# DSS_EDP0_COMMON_0_V2A_CORE_VP_REGS_APB register map
Vendor: Texas Instruments
Peripheral module from a debugger description file (folder J7_AHP).
Registers are 32-bit, access not given, reset 0x0 unless marked. A register's access mark holds for its fields unless they carry their own. Offsets are as the file gives them; lines under a group give offsets from that group; [hi:lo] are bit positions; {n}, {i} and the like mark numbered series; 'fields as' and 'values as' point back to an identical list; <NAME> marks a mode.

## DSS_EDP0_COMMON_0_V2A_CORE_VP_REGS_APB (part 1 of 3)
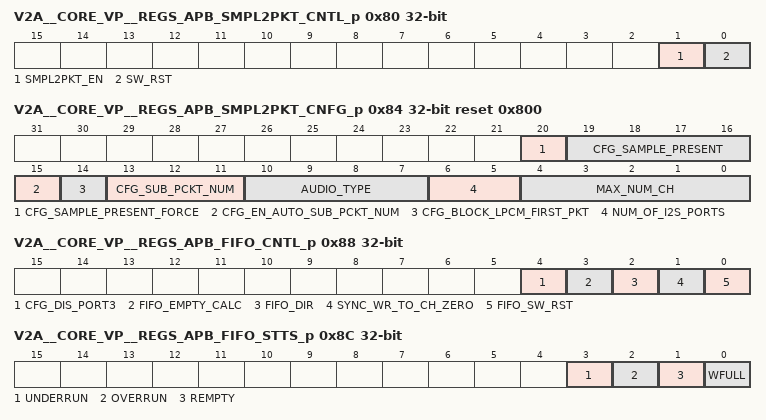
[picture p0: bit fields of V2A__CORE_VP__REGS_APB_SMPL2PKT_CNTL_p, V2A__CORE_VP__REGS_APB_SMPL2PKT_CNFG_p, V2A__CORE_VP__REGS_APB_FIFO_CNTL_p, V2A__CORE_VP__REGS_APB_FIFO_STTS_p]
0x80 V2A__CORE_VP__REGS_APB_SMPL2PKT_CNTL_p
  [1] SMPL2PKT_EN rw — When high Sample to Packets Block starts.
  [0] SW_RST rw — Software reset. Active high.
0x84 V2A__CORE_VP__REGS_APB_SMPL2PKT_CNFG_p reset 0x800
  [20] CFG_SAMPLE_PRESENT_FORCE rw — Force sample present bits
  [19:16] CFG_SAMPLE_PRESENT rw — Sample present bits if force them is active
  [15] CFG_EN_AUTO_SUB_PCKT_NUM rw — Enable automatics sub packet number. When enabled number of sub-packts will be set according to MEM FIFO number of samples.
  [14] CFG_BLOCK_LPCM_FIRST_PKT rw — 0 - All packets behave the same. 1- First lpcm audio packet is sent with 1 - SP.
  [13:11] CFG_SUB_PCKT_NUM rw — Number of sub-packets in HDMI audio 2-ch packet. 00: 1-SP 01: 2-SP 10: 3-SP 11: 4-SP. 100-111: NA.
  [10:7] AUDIO_TYPE rw — Audio Type setting. Packet is structured according to audio type.
  [6:5] NUM_OF_I2S_PORTS rw — Number ofactive I2S ports. 00- 1 port 01-2 ports 11- 4 ports 11 -NA.
  [4:0] MAX_NUM_CH rw — Number of channels to decode. 0: 1 channel 31: 32 channels
0x88 V2A__CORE_VP__REGS_APB_FIFO_CNTL_p
  [4] CFG_DIS_PORT3 rw — 0 - Normal Operation. 1 - I2S port 3 is disabled [user should ignore its outputs]. This allows for 24-ch, 12-ch, 6-ch transfer.
  [3] FIFO_EMPTY_CALC rw — 0 - Empty is a function of read address. 1 - Empty is a function of BASE read address.
  [2] FIFO_DIR rw — 0 - smpl2pkt [inc_step=number of I2S ports] 1 - pkt2smpl [inc_step=num_ch_per_port]
  [1] SYNC_WR_TO_CH_ZERO rw — When high the last channel index synchronizes the write addresses [to the next channel group]
  [0] FIFO_SW_RST rw — Resets Fifo's write and read pointers. When FIFO configuration bits change this signal should be high [due to synchronization issues].
0x8C V2A__CORE_VP__REGS_APB_FIFO_STTS_p
  [3] UNDERRUN ro — Indicates a FIFO underrun error has occured - FIFO read when it was empty. For debug purposes, not synchronized.
  [2] OVERRUN ro — Indicates a FIFO overrun error has occured - FIFO written to when it was full. For debug purposes, not synchronized.
  [1] REMPTY ro — Indicates FIFO Empty. For debug purposes, not synchronized.
  [0] WFULL ro — Indicates FIFO Full. For debug purposes, not synchronized.
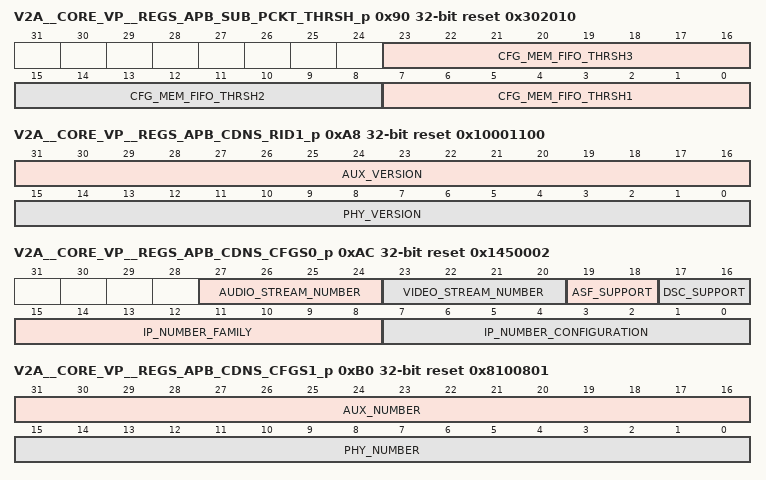
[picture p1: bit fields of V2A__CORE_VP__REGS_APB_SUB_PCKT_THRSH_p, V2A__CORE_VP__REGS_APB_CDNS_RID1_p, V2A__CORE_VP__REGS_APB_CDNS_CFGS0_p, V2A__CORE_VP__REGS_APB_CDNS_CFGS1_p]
0x90 V2A__CORE_VP__REGS_APB_SUB_PCKT_THRSH_p reset 0x302010
  [23:16] CFG_MEM_FIFO_THRSH3 rw — If number of samples in MEM FIFO is below Threshold 3: Each Packet will contain only 3 subpacket.
  [15:8] CFG_MEM_FIFO_THRSH2 rw — If number of samples in MEM FIFO is below Threshold2: Each Packet will contain only 2 subpacket.
  [7:0] CFG_MEM_FIFO_THRSH1 rw — If number of samples in MEM FIFO is below Threshold 1: Each Packet will contain only 1 subpacket.
0xA0 V2A__CORE_VP__REGS_APB_CDNS_DID_p ro reset 0x8546
  [31:0] IPVER — 0x8546 - DisplayPort 1.4/EmbeddedDisplayPort 1.4 Tx Combo Controller
0xA4 V2A__CORE_VP__REGS_APB_CDNS_RID0_p reset 0x2000
  [15:0] IP_VERSION ro — IP version: r[15:4]v[3:0]
0xA8 V2A__CORE_VP__REGS_APB_CDNS_RID1_p ro reset 0x10001100
  [31:16] AUX_VERSION — AUX version: r[31:20]v[19:16]
  [15:0] PHY_VERSION — PHY version: r[15:4]v[3:0]
0xAC V2A__CORE_VP__REGS_APB_CDNS_CFGS0_p reset 0x1450002
  [27:24] AUDIO_STREAM_NUMBER ro — Secondary configuration. Number of audio streams supported
  [23:20] VIDEO_STREAM_NUMBER ro — Secondary configuration. Number of video streams supported
  [19:18] ASF_SUPPORT ro — Secondary configuration. ASF support. 0x0: ASF not supported, 0x1: ASF supported
  [17:16] DSC_SUPPORT ro — Secondary configuration. DSC support. 0x0: DSC not supported, 0x1: DSC supported
  [15:8] IP_NUMBER_FAMILY ro — Main configuration. IP Family Code. 0x00: Display TX Controller, 0x01: Display RX Controller
  [7:0] IP_NUMBER_CONFIGURATION ro — Main configuration. IP configuration. 0x00 - HDMI+DP+HDPC 0x01 - HDMI+HDCP 0x02 - DP+HDCP 0x03 - HDMI+DP
0xB0 V2A__CORE_VP__REGS_APB_CDNS_CFGS1_p ro reset 0x8100801
  [31:16] AUX_NUMBER — AUX IP Number, according to versioning scheme.
  [15:0] PHY_NUMBER — PHY IP Number, according to versioning scheme.
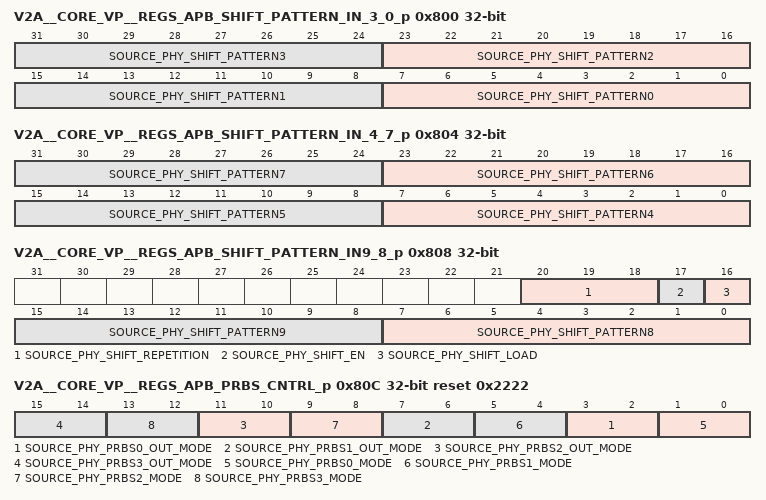
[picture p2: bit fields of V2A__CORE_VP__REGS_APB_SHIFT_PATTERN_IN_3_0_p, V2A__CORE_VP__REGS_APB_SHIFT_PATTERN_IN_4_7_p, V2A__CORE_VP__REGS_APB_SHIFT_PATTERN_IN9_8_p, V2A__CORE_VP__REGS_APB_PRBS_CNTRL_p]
0x800 V2A__CORE_VP__REGS_APB_SHIFT_PATTERN_IN_3_0_p rw
  [8n+7:8n] SOURCE_PHY_SHIFT_PATTERN{n} (n=0..3) — Input to hdmi_pattern_shift
0x804 V2A__CORE_VP__REGS_APB_SHIFT_PATTERN_IN_4_7_p rw
  [8n-25:8n-32] SOURCE_PHY_SHIFT_PATTERN{n} (n=4..7) — Input to hdmi_pattern_shift
0x808 V2A__CORE_VP__REGS_APB_SHIFT_PATTERN_IN9_8_p
  [20:18] SOURCE_PHY_SHIFT_REPETITION rw — Shift repetition Number
  [17] SOURCE_PHY_SHIFT_EN rw — When 1 enable the Shift pattern Mechanism
  [16] SOURCE_PHY_SHIFT_LOAD rw — When 1 load the 80 bits of data
  [15:8] SOURCE_PHY_SHIFT_PATTERN9 rw — Input to hdmi_pattern_shift
  [7:0] SOURCE_PHY_SHIFT_PATTERN8 rw — Input to hdmi_pattern_shift
0x80C V2A__CORE_VP__REGS_APB_PRBS_CNTRL_p reset 0x2222
  [4n+3:4n+2] SOURCE_PHY_PRBS{n}_OUT_MODE rw (n=0..3) — 00 = idle, output all zeros 01 = output 8 bits on pattern[7:0] 10 = output 1 bit on pattern[9] and output inverted bit on pattern[8] 11 = output 10 bits on pattern[9:0]
  [4n+1:4n] SOURCE_PHY_PRBS{n}_MODE rw (n=0..3) — 00 = PRBS11 01 = PRBS15 10 = PRBS7 11 = PRBS31
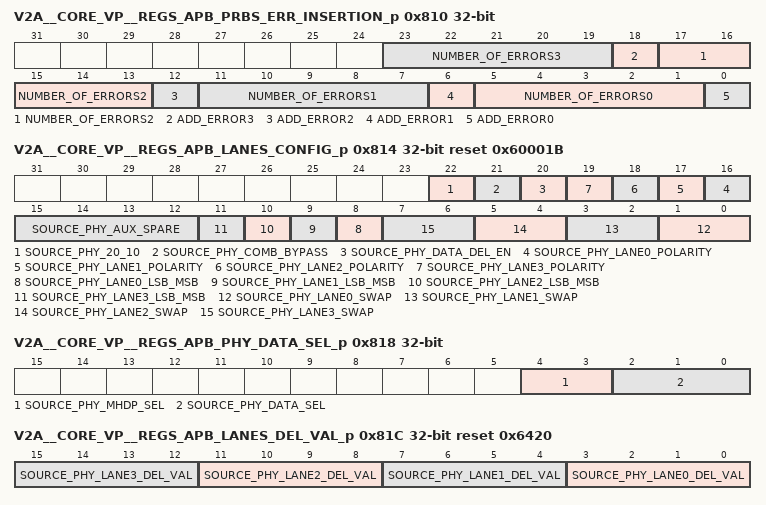
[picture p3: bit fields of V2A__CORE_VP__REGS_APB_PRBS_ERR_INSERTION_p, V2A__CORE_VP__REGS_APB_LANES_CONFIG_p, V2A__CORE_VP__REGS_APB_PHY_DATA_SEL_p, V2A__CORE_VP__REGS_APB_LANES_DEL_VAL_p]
0x810 V2A__CORE_VP__REGS_APB_PRBS_ERR_INSERTION_p
  [6n+5:6n+1] NUMBER_OF_ERRORS{n} rw (n=0..3) — The number of errors to be inserted when add_error is high.
  [18] ADD_ERROR3 rw — When high the PRBS generator inserts the number of errors written in number_of_errors field.
  [12] ADD_ERROR2 rw — When high the PRBS generator inserts the number of errors written in number_of_errors field.
  [6] ADD_ERROR1 rw — When high the PRBS generator inserts the number of errors written in number_of_errors field
  [0] ADD_ERROR0 rw — When high the PRBS generator inserts the number of errors written in number_of_errors field
0x814 V2A__CORE_VP__REGS_APB_LANES_CONFIG_p reset 0x60001B
  [22] SOURCE_PHY_20_10 rw — 1'b0: Data to PHY is 10 bit with char clock 1'd1: Data to PHY is 20 bit with data clock
  [21] SOURCE_PHY_COMB_BYPASS rw — Bypass swap invert and all combination
  [20] SOURCE_PHY_DATA_DEL_EN rw — enable configurable delay of lanes to be activated.if this bit is 0 the delay is only activated for DisplayPort mode with source_phy_data_sel=prbs or shift-mem
  [n+16] SOURCE_PHY_LANE{n}_POLARITY rw (n=0..3) — Reverse polarity of data, lane{n}
  [15:12] SOURCE_PHY_AUX_SPARE rw — Spare bits for aux **1.1**
  [n+8] SOURCE_PHY_LANE{n}_LSB_MSB rw (n=0..3) — Reverse order of data, lane{n}
  [2n+1:2n] SOURCE_PHY_LANE{n}_SWAP rw (n=0..3) — Swap control lane{n}
0x818 V2A__CORE_VP__REGS_APB_PHY_DATA_SEL_p
  [4:3] SOURCE_PHY_MHDP_SEL rw — 3'd0: tx_data = DP 3'd1: tx_data = HDMI 3'd2: tx_data = RSRV 3'd3: tx_data = RSRV
  [2:0] SOURCE_PHY_DATA_SEL rw — 3'd0: tx_data = phy_dout 3'd1: tx_data = phy_dout_bypass 3'd2: tx_data = source_phy_prbs_pout 3'd3: tx_data = source_phy_shift_pout
0x81C V2A__CORE_VP__REGS_APB_LANES_DEL_VAL_p reset 0x6420
  [4n+3:4n] SOURCE_PHY_LANE{n}_DEL_VAL rw (n=0..3) — delay for lane {n} this parameter can take values from 0 up to 8. All other values are reserved
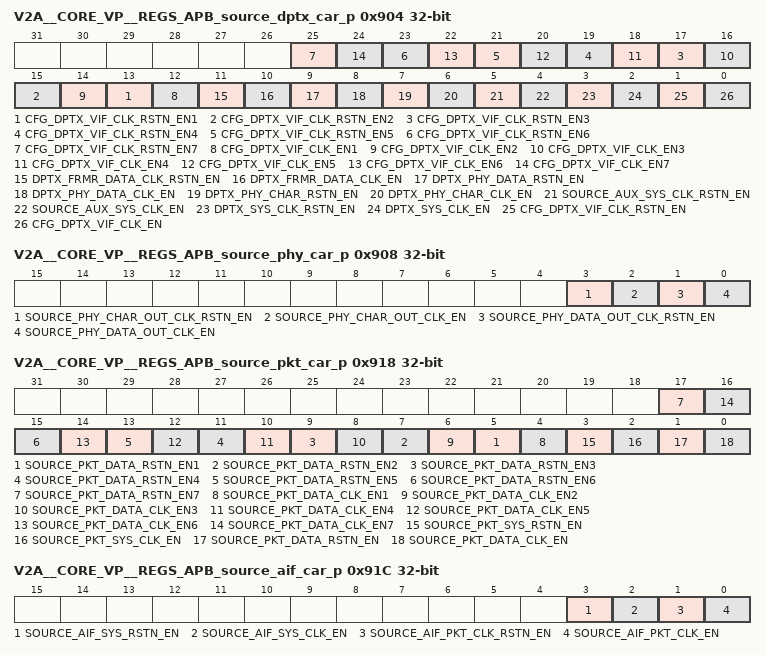
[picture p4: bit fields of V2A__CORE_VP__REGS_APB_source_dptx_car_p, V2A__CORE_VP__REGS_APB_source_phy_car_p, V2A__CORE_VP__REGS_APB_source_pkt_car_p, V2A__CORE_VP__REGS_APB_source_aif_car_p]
0x904 V2A__CORE_VP__REGS_APB_source_dptx_car_p
  [2n+11] CFG_DPTX_VIF_CLK_RSTN_EN{n} rw (n=1..7) — dptx_vif_clk_rstn enable for stream number {n} - active low
  [2n+10] CFG_DPTX_VIF_CLK_EN{n} rw (n=1..7) — dptx_vif_clk enable for stream number {n} - active high
  [11] DPTX_FRMR_DATA_CLK_RSTN_EN rw — dptx_frmr_data_clk_rstn enable - active low
  [10] DPTX_FRMR_DATA_CLK_EN rw — dptx_frmr_data_clk enable - active high
  [9] DPTX_PHY_DATA_RSTN_EN rw — dptx_phy_data_rstn enable - active low
  [8] DPTX_PHY_DATA_CLK_EN rw — dptx_phy_data_clk enable - active high
  [7] DPTX_PHY_CHAR_RSTN_EN rw — dptx_phy_char_rstn enable - active low
  [6] DPTX_PHY_CHAR_CLK_EN rw — dptx_phy_char_clk enable - active high
  [5] SOURCE_AUX_SYS_CLK_RSTN_EN rw — source_aux_sys_clk_rstn enable - active low
  [4] SOURCE_AUX_SYS_CLK_EN rw — source_aux_sys_clk enable - active high
  [3] DPTX_SYS_CLK_RSTN_EN rw — dptx_sys_clk_rstn enable - active low
  [2] DPTX_SYS_CLK_EN rw — dptx_sys_clk enable - active high
  [1] CFG_DPTX_VIF_CLK_RSTN_EN rw — dptx_vif_clk_rstn enable - active low
  [0] CFG_DPTX_VIF_CLK_EN rw — dptx_vif_clk enable - active high
0x908 V2A__CORE_VP__REGS_APB_source_phy_car_p
  [3] SOURCE_PHY_CHAR_OUT_CLK_RSTN_EN rw — source_phy_char_out_clk_rstn enable - active low
  [2] SOURCE_PHY_CHAR_OUT_CLK_EN rw — source_phy_char_out_clk enable - active high
  [1] SOURCE_PHY_DATA_OUT_CLK_RSTN_EN rw — source_phy_data_out_clk_rstn enable - active low
  [0] SOURCE_PHY_DATA_OUT_CLK_EN rw — source_phy_data_out_clk enable - active high
0x918 V2A__CORE_VP__REGS_APB_source_pkt_car_p
  [2n+3] SOURCE_PKT_DATA_RSTN_EN{n} rw (n=1..7) — source_pkt_data_rstn_en{n} - active low
  [2n+2] SOURCE_PKT_DATA_CLK_EN{n} rw (n=1..7) — source_pkt_data_clk_en{n} - active high
  [3] SOURCE_PKT_SYS_RSTN_EN rw — source_pkt_sys_rstn_en - active low
  [2] SOURCE_PKT_SYS_CLK_EN rw — source_pkt_sys_clk_en - active high
  [1] SOURCE_PKT_DATA_RSTN_EN rw — source_pkt_data_rstn_en - active low
  [0] SOURCE_PKT_DATA_CLK_EN rw — source_pkt_data_clk_en - active high
0x91C V2A__CORE_VP__REGS_APB_source_aif_car_p
  [3] SOURCE_AIF_SYS_RSTN_EN rw — source_aif_sys_rstn enable - active low
  [2] SOURCE_AIF_SYS_CLK_EN rw — source_aif_sys_clk enable - active high
  [1] SOURCE_AIF_PKT_CLK_RSTN_EN rw — source_aif_pkt_clk_rstn enable - active low
  [0] SOURCE_AIF_PKT_CLK_EN rw — source_aif_pkt_clk enable - active high
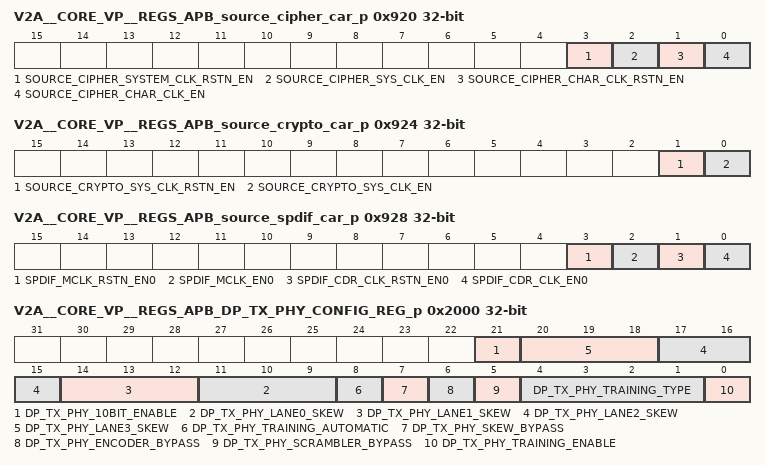
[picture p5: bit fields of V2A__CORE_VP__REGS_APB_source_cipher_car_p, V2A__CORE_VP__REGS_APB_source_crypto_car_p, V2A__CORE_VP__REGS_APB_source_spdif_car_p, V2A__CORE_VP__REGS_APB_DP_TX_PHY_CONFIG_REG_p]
0x920 V2A__CORE_VP__REGS_APB_source_cipher_car_p
  [3] SOURCE_CIPHER_SYSTEM_CLK_RSTN_EN rw — source_cipher_system_clk_rstn enable - active low [Only when HDCP used]
  [2] SOURCE_CIPHER_SYS_CLK_EN rw — source_cipher_sys_clk enable - active high [Only when HDCP used]
  [1] SOURCE_CIPHER_CHAR_CLK_RSTN_EN rw — source_cipher_char_clk_rstn enable - active low [Only when HDCP used]
  [0] SOURCE_CIPHER_CHAR_CLK_EN rw — source_cipher_char_clk enable - active high [Only when HDCP used]
0x924 V2A__CORE_VP__REGS_APB_source_crypto_car_p
  [1] SOURCE_CRYPTO_SYS_CLK_RSTN_EN rw — source_crypto_sys_clk_rstn enable - active low [Only when HDCP used]
  [0] SOURCE_CRYPTO_SYS_CLK_EN rw — source_crypto_sys_clk enable - active high [Only when HDCP used]
0x928 V2A__CORE_VP__REGS_APB_source_spdif_car_p
  [3] SPDIF_MCLK_RSTN_EN0 rw — spdif_mclk_rstn enable0 - active low
  [2] SPDIF_MCLK_EN0 rw — spdif_mclk enable0 - active high
  [1] SPDIF_CDR_CLK_RSTN_EN0 rw — spdif_cdr_clk_rstn enable0 - active low
  [0] SPDIF_CDR_CLK_EN0 rw — spdif_cdr_clk enable0 - active high
0x2000 V2A__CORE_VP__REGS_APB_DP_TX_PHY_CONFIG_REG_p
  [21] DP_TX_PHY_10BIT_ENABLE rw — Used to enable the 10-bit mode. Active high.
  [3n+11:3n+9] DP_TX_PHY_LANE{n}_SKEW rw (n=0..3) — Specifies the programmable lane{n} skew.
  [8] DP_TX_PHY_TRAINING_AUTOMATIC rw — When set, the dp_tx_phy_scrambler_bypass and the dp_tx_phy_encoder_bypass bits are ignored during training pattern generation. This is a debug feature.
  [7] DP_TX_PHY_SKEW_BYPASS rw — Used to bypass the lane skew. Active high. This is a debug feature.
  [6] DP_TX_PHY_ENCODER_BYPASS rw — Used to bypass the encoder. Active high. This is a debug feature.
  [5] DP_TX_PHY_SCRAMBLER_BYPASS rw — Used to bypass the scrambler. Active high. This is a debug feature.
  [4:1] DP_TX_PHY_TRAINING_TYPE rw — Specifies the training pattern type used as follows: 0000 PRBS7 0001 TPS1 0010 TPS2 0011 TPS3 0100 TPS4 0101 custom 80-bit pattern 0110 D10.2 training pattern 0111 Symbol Error Rate Measurement pattern 1000 CP2520 pattern1 1001 CP2520 pattern2 1010 CP2520 pattern3 others reserved
  [0] DP_TX_PHY_TRAINING_ENABLE rw — Enables the training sequence [when set to 1].
0x2004 V2A__CORE_VP__REGS_APB_DP_TX_PHY_SW_RESET_p
  [0] DP_TX_PHY_SW_RST rw — Software reset. Active high.
0x2008 V2A__CORE_VP__REGS_APB_DP_TX_PHY_SCRAMBLER_SEED_p reset 0xFFFF
  [15:0] DP_TX_PHY_SCRAMBLER_SEED rw — Scrambler seed range 0-0xFFFF
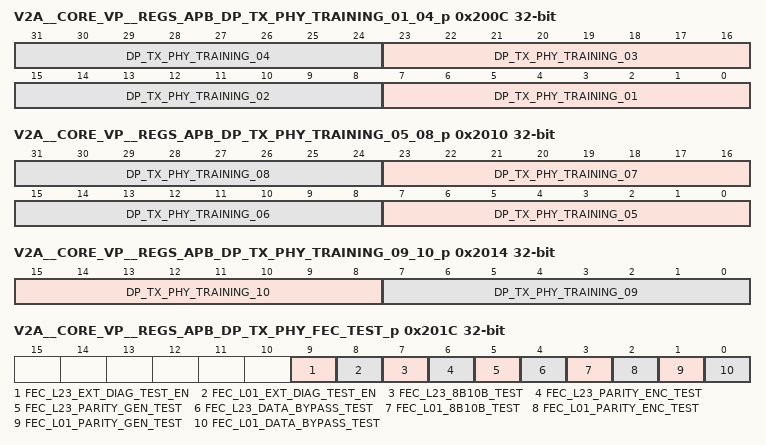
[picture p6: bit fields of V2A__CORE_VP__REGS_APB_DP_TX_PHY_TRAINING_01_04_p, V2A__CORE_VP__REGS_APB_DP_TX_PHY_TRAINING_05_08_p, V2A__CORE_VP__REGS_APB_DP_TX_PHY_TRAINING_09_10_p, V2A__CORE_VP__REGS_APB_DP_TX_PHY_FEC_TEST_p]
0x200C V2A__CORE_VP__REGS_APB_DP_TX_PHY_TRAINING_01_04_p rw
  [8n-1:8n-8] DP_TX_PHY_TRAINING_{n:02} (n=1..4) — Byte {n} of the 80-bit custom training data.
0x2010 V2A__CORE_VP__REGS_APB_DP_TX_PHY_TRAINING_05_08_p rw
  [8n-33:8n-40] DP_TX_PHY_TRAINING_{n:02} (n=5..8) — Byte {n} of the 80-bit custom training data.
0x2014 V2A__CORE_VP__REGS_APB_DP_TX_PHY_TRAINING_09_10_p
  [15:8] DP_TX_PHY_TRAINING_10 rw — Byte 10 of the 80-bit custom training data.
  [7:0] DP_TX_PHY_TRAINING_09 rw — Byte 9 of the 80-bit custom training data.
0x2018 V2A__CORE_VP__REGS_APB_DP_TX_PHY_SR_INTERVAL_p reset 0xFC
  [15:0] DP_TX_PHY_SR_INTERVAL rw — CP2520 test pattern SR Interval definition
0x201C V2A__CORE_VP__REGS_APB_DP_TX_PHY_FEC_TEST_p
  [9] FEC_L23_EXT_DIAG_TEST_EN rw — Encoder 1 external diagnostic test enable. When asserted, a corruption is injected in the external diagnostic reference module which generate an external diagnostic support module fault. To perform external diagnostic test this bit must be set first and then one of the bits 7-4 must be set. Both must be a separate writes. NOTE: This bit cannot be set when bypess, encoder, decoder or 8b10b tests are performed.
  [8] FEC_L01_EXT_DIAG_TEST_EN rw — Encoder 0 external diagnostic test enable. When asserted, a corruption is injected in the external diagnostic reference module which generate an external diagnostic support module fault. To perform external diagnostic test this bit must be set first and then one of the bits 3-0 must be set. Both must be a separate writes. NOTE: This bit cannot be set when bypess, encoder, decoder or 8b10b tests are performed.
  [7] FEC_L23_8B10B_TEST rw — When asserted, a corruption is injected at the interface of the internal diagnostic module which generate a fault in the 8b10b check of the FEC IP datapath for lanes 2 and 3. Bit is self cleared.
  [6] FEC_L23_PARITY_ENC_TEST rw — When asserted, a corruption is injected at the interface of the internal diagnostic module which generate a fault in the parity enc check of the FEC IP datapath for lanes 2 and 3. Bit is self cleared.
  [5] FEC_L23_PARITY_GEN_TEST rw — When asserted, a corruption is injected at the interface of the internal diagnostic module which generate a fault in the parity gen check of the FEC IP datapaths for lanes 2 and 3. Bit is self cleared.
  [4] FEC_L23_DATA_BYPASS_TEST rw — When asserted, a corruption is injected at the interface of the internal diagnostic module which generate a fault in the bypass check for of the FEC IP datapathe for lanes 2 and 3. Bit is self cleared.
  [3] FEC_L01_8B10B_TEST rw — When asserted, a corruption is injected at the interface of the internal diagnostic module which generate a fault in the 8b10b check of the FEC IP datapath for lanes 0 and 1. Bit is self cleared.
  [2] FEC_L01_PARITY_ENC_TEST rw — When asserted, a corruption is injected at the interface of the internal diagnostic module which generate a fault in the parity enc check of the FEC IP datapath for lanes 0 and 1. Bit is self cleared.
  [1] FEC_L01_PARITY_GEN_TEST rw — When asserted, a corruption is injected at the interface of the internal diagnostic module which generate a fault in the parity gen check of the FEC IP datapath for lanes 0 and 1. Bit is self cleared.
  [0] FEC_L01_DATA_BYPASS_TEST rw — When asserted, a corruption is injected at the interface of the internal diagnostic module which generate a fault in the bypass check for of the FEC IP datapath for lanes 0 and 1. Bit is self cleared.
0x2100 V2A__CORE_VP__REGS_APB_HPD_IRQ_DET_MIN_TIMER_p reset 0xC350
  [23:0] HPD_IRQ_DET_MIN_TIMER rw — HPD min timer for interrupt.
0x2104 V2A__CORE_VP__REGS_APB_HPD_IRQ_DET_MAX_TIMER_p reset 0x186A0
  [23:0] HPD_IRQ_DET_MAX_TIMER rw — HPD max timer
0x2108 V2A__CORE_VP__REGS_APB_HPD_UNPLGED_DET_MIN_TIMER_p reset 0x30D40
  [23:0] HPD_UNPLGED_DET_MIN_TIMER rw — HPD unplugged timer
0x210C V2A__CORE_VP__REGS_APB_HPD_STABLE_TIMER_p reset 0x186A0
  [23:0] HPD_STABLE_TIMER rw — HPD stable timer counter setup.
0x2110 V2A__CORE_VP__REGS_APB_HPD_FILTER_TIMER_p reset 0x7A12
  [23:0] HPD_FILTER_TIMER rw — HPD glitch filter counter setup.
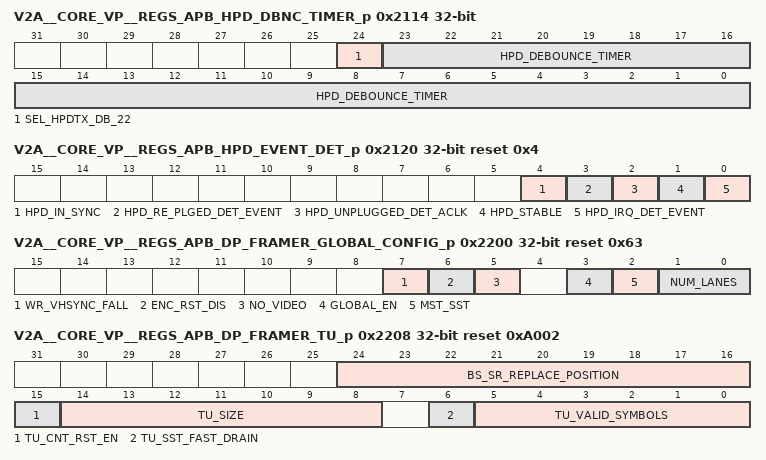
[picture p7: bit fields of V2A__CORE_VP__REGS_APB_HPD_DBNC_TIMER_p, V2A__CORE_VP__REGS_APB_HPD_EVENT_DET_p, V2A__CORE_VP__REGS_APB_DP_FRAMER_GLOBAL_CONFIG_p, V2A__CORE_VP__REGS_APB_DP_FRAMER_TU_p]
0x2114 V2A__CORE_VP__REGS_APB_HPD_DBNC_TIMER_p
  [24] SEL_HPDTX_DB_22 rw — Debouncer enable 0 - debouncer disabled 1 - debouncer enabled
  [23:0] HPD_DEBOUNCE_TIMER rw — HPD debounce timer setup.
0x211C V2A__CORE_VP__REGS_APB_HPD_EVENT_MASK_p
  [3:0] HPD_EVENTS_MASK rw — HPD mask events
0x2120 V2A__CORE_VP__REGS_APB_HPD_EVENT_DET_p reset 0x4
  [4] HPD_IN_SYNC ro — HDP in sync detected
  [3] HPD_RE_PLGED_DET_EVENT ro — HPD Re-Plugged event detected.
  [2] HPD_UNPLUGGED_DET_ACLK ro — HPD Un-Plugged event detected.
  [1] HPD_STABLE ro — HPD Stable indication
  [0] HPD_IRQ_DET_EVENT ro — Bit 0 - HPD irq event
0x2200 V2A__CORE_VP__REGS_APB_DP_FRAMER_GLOBAL_CONFIG_p reset 0x63
  [7] WR_VHSYNC_FALL rw — When set to 1 change the write state machine to sync on falling edge of vsync. Used only for debug purpose.
  [6] ENC_RST_DIS rw — Unused. Kept RW for software backward compatibility.
  [5] NO_VIDEO rw — No-video mode configuration bit. Relevant only in SST mode. When this bit is set high and framer is enabled then IP operates in no-video mode i.e. BS symbol is generated every 8192 link symbols. In this mode audio data can be transmitted.
  [3] GLOBAL_EN rw — Global enable for complete Framer module, active high. It is deasserted during configuration phase. Once configuration is finished, it is asserted.
  [2] MST_SST rw — Mode select: 0 - SST mode 1 - MST mode Static cofiguration bit that must be set before link training.
  [1:0] NUM_LANES rw — Number of lanes: 0h - One lane [Lane 0 only] 1h - Two lanes [Lanes 0 and 1 only] 2h - Reserved 3h - Four lanes [Lanes 0, 1, 2, and 3]. This value can only be changed before link training and further it can by modified during link training in case link training for a given lane configuration fails. This field must not be changed after link training.
0x2204 V2A__CORE_VP__REGS_APB_DP_SW_RESET_p
  [0] SW_RST rw — Unused. Kept RW for software backward compatibility.
0x2208 V2A__CORE_VP__REGS_APB_DP_FRAMER_TU_p reset 0xA002
  [24:16] BS_SR_REPLACE_POSITION rw — Static debug register. When set to non-zero value, the BS counter will be reinitialized to this value that will result in earlier initial SR insertion.
  [15] TU_CNT_RST_EN rw — Unused. Kept RW for software backward compatibility.
  [14:8] TU_SIZE rw — Transfer Unit size. Even values between 32 and 64 are supported.
  [6] TU_SST_FAST_DRAIN rw — Allow the video FIFO to drain faster at end of line. This setting applies only to SST mode.
  [5:0] TU_VALID_SYMBOLS rw — Number of valid symbols per Transfer Unit [TU]. Rounded down to lower integer value [refer to equation in DP specification]. Allowed values are 1 to [TU_size-1]. TU valid smaller than one that would result this register to be set to 0 are not supported by the IP. This setting applies only to SST mode.
0x2218 V2A__CORE_VP__REGS_APB_DP_FRAMER_BS_SR_INTRVL_p reset 0x200
  [9:0] BS_SR_INTERVAL rw — Static debug register. Controls how often BS is replaced by SR in SST mode. Default value of 512 results in every 512th BS being replaced by SR as per DP spec. This register can only be changed for a test purposes in order to speed up BS-SR replacement.
0x2258 V2A__CORE_VP__REGS_APB_DP_MTPH_ECF_SLOTS_31_0_p rw
  [31:0] TSLOT_ENCRYPT31_0
0x225C V2A__CORE_VP__REGS_APB_DP_MTPH_ECF_SLOTS_63_32_p rw
  [31:0] TSLOT_ENCRYPT63_32
0x2260 V2A__CORE_VP__REGS_APB_DP_MTPH_LVP_SYMBOL_p reset 0x531F
  [15:0] MTPH_LVP_SYM rw — Symbol value for LINK VERIFICATION PATTERN [LVP]
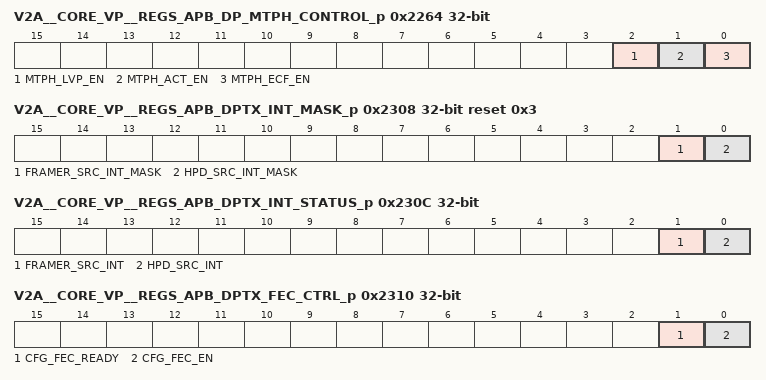
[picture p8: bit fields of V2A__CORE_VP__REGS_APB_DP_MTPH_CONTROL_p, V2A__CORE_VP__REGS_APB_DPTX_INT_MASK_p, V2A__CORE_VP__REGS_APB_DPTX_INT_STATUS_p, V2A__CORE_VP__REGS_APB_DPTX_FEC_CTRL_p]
0x2264 V2A__CORE_VP__REGS_APB_DP_MTPH_CONTROL_p
  [2] MTPH_LVP_EN rw — Unused. Kept RW for software backward compatibility.
  [1] MTPH_ACT_EN wo — MST feature when written with value 1, an ACT sequence will be triggered for slot allocation control. This bit is write only.
  [0] MTPH_ECF_EN rw — Unused. Kept RW for software backward compatibility.
0x226C V2A__CORE_VP__REGS_APB_DP_MTPH_STATUS_p
  [0] MTPH_ACT_STATUS ro — Status of ACT insertion. Returns 1 until ACT sequence completes.
0x2300 V2A__CORE_VP__REGS_APB_DPTX_LANE_EN_p
  [3:0] DPTX_LANE_ENABLE rw — DPTX lane enable each lane as a bit when 1 lane is enabled
0x2304 V2A__CORE_VP__REGS_APB_DPTX_ENHNCD_p
  [0] DPTX_ENHANCED_MODE rw — Enhanced mode control 0x0 - enhanced mode disabled 0x1 - enhanced mode enabled. Enhanced mode should always be enabled if Sink supports it.
0x2308 V2A__CORE_VP__REGS_APB_DPTX_INT_MASK_p reset 0x3
  [1] FRAMER_SRC_INT_MASK rw — Framer mask interrupt 0x0-interrupt enabled 0x1-interrupt disabled
  [0] HPD_SRC_INT_MASK rw — HPD mask interrupt 0x0-interrupt enabled 0x1-interrupt disabled
0x230C V2A__CORE_VP__REGS_APB_DPTX_INT_STATUS_p
  [1] FRAMER_SRC_INT ro — Framer interrupt - not used.
  [0] HPD_SRC_INT ro — HPD interrupt. Active HIGH. If set further status can be read from HPD_EVENT_DET register. This bit is automatically cleared on read from HPD_EVENT_DET register.
0x2310 V2A__CORE_VP__REGS_APB_DPTX_FEC_CTRL_p
  [1] CFG_FEC_READY rw — Equivalent DPCD register FEC_READY, enable alternative CP coding. This bit must be set high before link training if FEC is going to be enabled.
  [0] CFG_FEC_EN rw — FEC Enable 1-enabled 0-disabled. This bit can be changed on when there is no video transmission [and cfg_fec_ready was set before link training].
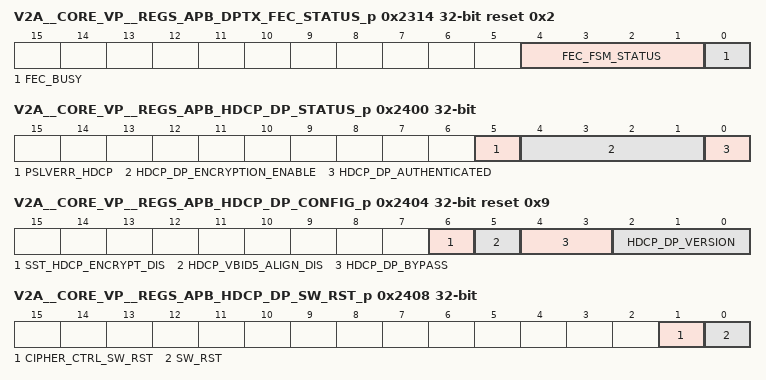
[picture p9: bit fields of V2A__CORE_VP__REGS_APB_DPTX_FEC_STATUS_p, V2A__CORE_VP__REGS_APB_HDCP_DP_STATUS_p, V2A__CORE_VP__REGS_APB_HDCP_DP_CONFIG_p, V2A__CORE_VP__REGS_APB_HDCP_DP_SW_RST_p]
0x2314 V2A__CORE_VP__REGS_APB_DPTX_FEC_STATUS_p reset 0x2
  [4:1] FEC_FSM_STATUS ro — FEC FSM status, 1-FEC is off, 2-generate enable sequence, 4-normal work, 8-generate disable sequence. Used for debug purposes only.
  [0] FEC_BUSY ro — FEC Active status. Set in line with first symbol of FEC_DECODE_EN sequence and de-asserts in line with last symbol of FEC_DECODE_DIS sequence.
0x2400 V2A__CORE_VP__REGS_APB_HDCP_DP_STATUS_p
  [5] PSLVERR_HDCP ro — APB slave error status from HDCP module has been reported when this bit is set to 1.
  [4:1] HDCP_DP_ENCRYPTION_ENABLE ro — Encryption is enabled when this bit is set to 1.
  [0] HDCP_DP_AUTHENTICATED ro — HDCP 1.3 authentication is enabled when this bit is set to 1.
0x2404 V2A__CORE_VP__REGS_APB_HDCP_DP_CONFIG_p reset 0x9
  [6] SST_HDCP_ENCRYPT_DIS rw — Disable automatic HDCP encryption in SST mode when cipher is authenticated. This bit can also be set to 1 to disable encryption
  [5] HDCP_VBID5_ALIGN_DIS rw — Debug register, no longer used.
  [4:3] HDCP_DP_BYPASS rw — HDCP DP bypass. No-bypass must be set prior link training if HDCP is going to be used. This field must not be changed during operation. 0x0-No bypass; 0x1-Bypass enabled; All other combinations reserved.
  [2:0] HDCP_DP_VERSION rw — HDCP version. 0x1-HDCP2.2; 0x2-HDCP1.4; Other-Reserved
0x2408 V2A__CORE_VP__REGS_APB_HDCP_DP_SW_RST_p
  [1] CIPHER_CTRL_SW_RST rw — Software reset of cipher control logic only.
  [0] SW_RST rw — Software reset.
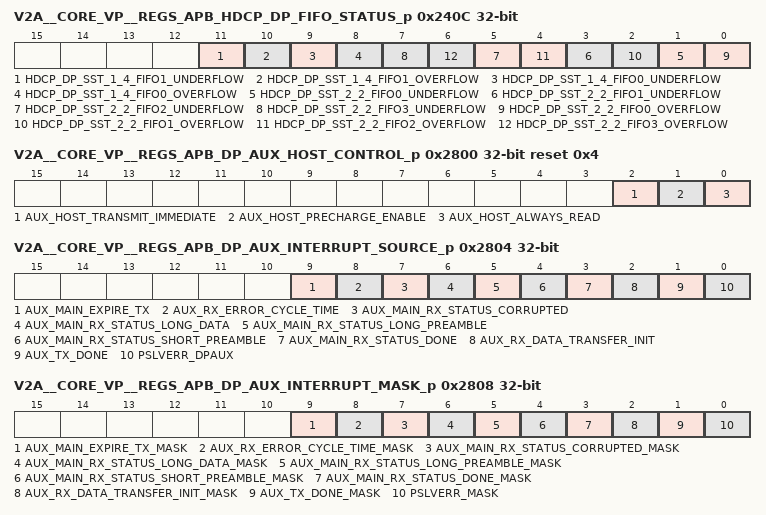
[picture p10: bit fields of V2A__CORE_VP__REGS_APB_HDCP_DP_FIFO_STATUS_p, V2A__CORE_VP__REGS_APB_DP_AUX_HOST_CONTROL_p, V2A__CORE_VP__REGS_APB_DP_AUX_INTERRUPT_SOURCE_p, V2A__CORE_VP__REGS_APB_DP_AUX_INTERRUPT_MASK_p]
0x240C V2A__CORE_VP__REGS_APB_HDCP_DP_FIFO_STATUS_p
  [11] HDCP_DP_SST_1_4_FIFO1_UNDERFLOW ro — SST HDCP1.4 fifo1 underflow.
  [10] HDCP_DP_SST_1_4_FIFO1_OVERFLOW ro — SST HDCP1.4 fifo1 overflow.
  [9] HDCP_DP_SST_1_4_FIFO0_UNDERFLOW ro — SST HDCP1.4 fifo0 underflow.
  [8] HDCP_DP_SST_1_4_FIFO0_OVERFLOW ro — SST HDCP1.4 fifo0 overflow.
  [2n+1] HDCP_DP_SST_2_2_FIFO{n}_UNDERFLOW ro (n=0..3) — SST HDCP2.2 fifo{n} underflow.
  [2n] HDCP_DP_SST_2_2_FIFO{n}_OVERFLOW ro (n=0..3) — SST HDCP2.2 fifo{n} overflow.
0x2800 V2A__CORE_VP__REGS_APB_DP_AUX_HOST_CONTROL_p reset 0x4
  [2] AUX_HOST_TRANSMIT_IMMEDIATE rw — This bit is used only in DP_OUT mode. If SET, a transaction that comes from the adapter will be sent immediately without waiting for send_external_transaction pulse. If CLEAR, the MC controls the traffic to/from the adapter.
  [1] AUX_HOST_PRECHARGE_ENABLE rw — According to the current standard the tx precharge is done by sending 10 to 16 data_0 on the line before the SYNC. Old standard define the precharge by forcing the AFE to be in precharge mode before transmitting the SYNC.
  [0] AUX_HOST_ALWAYS_READ rw — Normally, the aux_rx is disabled during transmit. Setting this bit allow loopback operation and all transmit transactions will go to the receiver. Used for debug purpose.
0x2804 V2A__CORE_VP__REGS_APB_DP_AUX_INTERRUPT_SOURCE_p
  [9] AUX_MAIN_EXPIRE_TX ro — Timer expire [external] in DP_OUT. Active HIGH. Clear on read.
  [8] AUX_RX_ERROR_CYCLE_TIME ro — Cycle time error. Asserted if aux_rx_last_cycle is less then aux_host_1m_min or greater then aux_host_1m_max. Active HIGH. Clear on read.
  [7] AUX_MAIN_RX_STATUS_CORRUPTED ro — The received transaction corrupted during the data phase [bad STOP, or unaligned STOP]. Active HIGH. Clear on read.
  [6] AUX_MAIN_RX_STATUS_LONG_DATA ro — The received transaction had more than 20 data bytes. Active HIGH. Clear on read.
  [5] AUX_MAIN_RX_STATUS_LONG_PREAMBLE ro — The received transaction had preamble greater than the preamble_max. Active HIGH. Clear on read.
  [4] AUX_MAIN_RX_STATUS_SHORT_PREAMBLE ro — The received transaction had preamble shorter than the preamble_max. Active HIGH. Clear on read.
  [3] AUX_MAIN_RX_STATUS_DONE ro — This module control the packet extraction and packet read from the memory. Active HIGH. Clear on read.
  [2] AUX_RX_DATA_TRANSFER_INIT ro — Rx data transfer may be initiated. Falling edge of the aux_mailbox_empty. Active HIGH. Clear on read.
  [1] AUX_TX_DONE ro — Tx data transfer finished. Active HIGH. Clear on read.
  [0] PSLVERR_DPAUX ro — APB slave error interrupt from DP AUX module. Active HIGH. Clear on read.
0x2808 V2A__CORE_VP__REGS_APB_DP_AUX_INTERRUPT_MASK_p
  [9] AUX_MAIN_EXPIRE_TX_MASK rw — aux_main_expire_external mask 0x0-interrupt enabled 0x1-interrupt disabled
  [8] AUX_RX_ERROR_CYCLE_TIME_MASK rw — aux_rx_error_cycle_time mask 0x0-interrupt enabled 0x1-interrupt disabled
  [7] AUX_MAIN_RX_STATUS_CORRUPTED_MASK rw — aux_main_rx_status_corrupted_mask 0x0-interrupt enabled 0x1-interrupt disabled
  [6] AUX_MAIN_RX_STATUS_LONG_DATA_MASK rw — aux_main_rx_status_long_data_mask 0x0-interrupt enabled 0x1-interrupt disabled
  [5] AUX_MAIN_RX_STATUS_LONG_PREAMBLE_MASK rw — aux_main_rx_status_long_preamble_mask 0x0-interrupt enabled 0x1-interrupt disabled
  [4] AUX_MAIN_RX_STATUS_SHORT_PREAMBLE_MASK rw — aux_main_rx_status_short_preamble_mask 0x0-interrupt enabled 0x1-interrupt disabled
  [3] AUX_MAIN_RX_STATUS_DONE_MASK rw — aux_main_rx_status_done_mask 0x0-interrupt enabled 0x1-interrupt disabled
  [2] AUX_RX_DATA_TRANSFER_INIT_MASK rw — rx_data_transfer_init mask 0x0-interrupt enabled 0x1-interrupt disabled
  [1] AUX_TX_DONE_MASK rw — aux_tx_done_mask 0x0-interrupt enabled 0x1-interrupt disabled
  [0] PSLVERR_MASK rw — Mask for pslverr_dpaux interrupt. 0x0-interrupt enabled 0x1-interrupt disabled
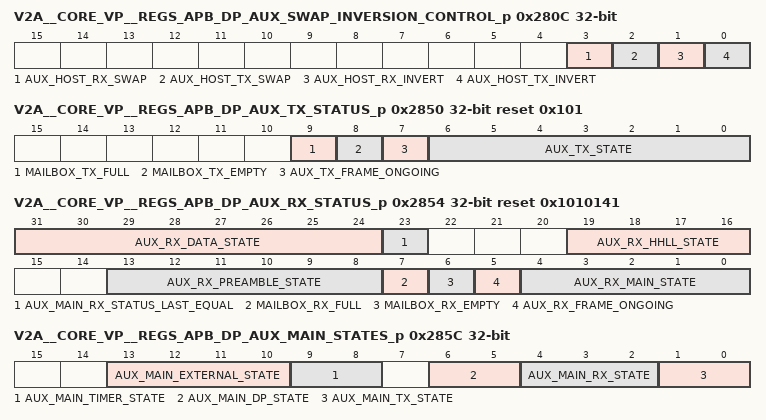
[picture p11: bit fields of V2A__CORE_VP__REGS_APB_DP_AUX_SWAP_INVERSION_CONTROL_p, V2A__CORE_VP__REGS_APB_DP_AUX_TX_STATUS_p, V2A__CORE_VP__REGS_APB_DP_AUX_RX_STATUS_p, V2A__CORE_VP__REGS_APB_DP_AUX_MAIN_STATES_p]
0x280C V2A__CORE_VP__REGS_APB_DP_AUX_SWAP_INVERSION_CONTROL_p
  [3] AUX_HOST_RX_SWAP rw — Shift right [LSB first] of the income data
  [2] AUX_HOST_TX_SWAP rw — Shift right the output data [LSB first]
  [1] AUX_HOST_RX_INVERT rw — Invert rx input and output data to AUXILIARY CHANNEL
  [0] AUX_HOST_TX_INVERT rw — Invert tx input and output data to AUXILIARY CHANNEL
0x2810 V2A__CORE_VP__REGS_APB_DP_AUX_SEND_NACK_TRANSACTION_p
  [0] AUX_HOST_SEND_NACK_TRANSACTION rw — Send nack transaction by AUX_TX. This bit is automatically cleared when operation in completed.
0x2814 V2A__CORE_VP__REGS_APB_DP_AUX_CLEAR_RX_p
  [0] AUX_HOST_CLEAR_RX rw — Clear all rx bits in register 64,65.This command is an indication that the processing of last receive transaction was completed and the AUX_RX can start looking for new receive transaction. This bit is automatically cleared when operation in completed.
0x2818 V2A__CORE_VP__REGS_APB_DP_AUX_CLEAR_TX_p
  [0] AUX_HOST_CLEAR_TX rw — Clear all external bits in registers 64,67.This command used in DP_IN mode. It is an indication that the processing of last external transaction was completed and the DP_AUX can start receive new external transaction from the adapter. This bit is automatically cleared when operation in completed.
0x281C V2A__CORE_VP__REGS_APB_DP_AUX_TIMER_STOP_p
  [0] AUX_HOST_STOP_TIMER rw — Stop timer operation.
0x2820 V2A__CORE_VP__REGS_APB_DP_AUX_TIMER_CLEAR_p
  [0] AUX_HOST_CLEAR_TIMER rw — Stop timer operation. This bit is automatically cleared when operation in completed.
0x2824 V2A__CORE_VP__REGS_APB_DP_AUX_RESET_SW_p
  [0] AUX_HOST_SW_RESET rw — Reset all DP_AUX state machines and clear all the status bits. The registers value remains. [S/W reset]. This bit is automatically cleared when operation in completed.
0x2828 V2A__CORE_VP__REGS_APB_DP_AUX_DIVIDE_2M_p reset 0xB
  [7:0] AUX_HOST_DIVIDE_2M rw — The ratio between sys_clk and 2MHz, [[sys_clk frequency/2MHz] - 1], for 25MHz sys_clk the value is 11. This register is used by AUX_TX for generating the AUX_TX clock.
0x282C V2A__CORE_VP__REGS_APB_DP_AUX_TX_PREACHARGE_LENGTH_p reset 0x10
  [5:0] AUX_HOST_PRECHARGE_LENGTH rw — Length of pre charge field, standard definition is 10 to 16 bits/clocks.
0x2830 V2A__CORE_VP__REGS_APB_DP_AUX_FREQUENCY_1M_MAX_p reset 0x22
  [10:0] AUX_HOST_1M_MAX rw — The maximum legal frequency receiving from the line by the standard is 1.25MHz.The calculation is:[1.25 MHz cycle time]/[sys_clk[-15%] cycle time] 800/46 =17
0x2834 V2A__CORE_VP__REGS_APB_DP_AUX_FREQUENCY_1M_MIN_p reset 0x9
  [10:0] AUX_HOST_1M_MIN rw — The minimum legal frequency receiving from the line by the standard is 0.83MHz.The calculation is:[0.83 MHz cycle time]/[sys_clk[+15%] cycle time] 1200/34 =35
0x2838 V2A__CORE_VP__REGS_APB_DP_AUX_RX_PRE_MIN_p reset 0x1A
  [5:0] AUX_HOST_PRE_MIN rw — Valid minimum length of preamble during receive. The standard defines pre_min=26 The value of this register should be greater then the average_number_of_cycles defined in reg 0 [2 , 4 or 8 ]
0x283C V2A__CORE_VP__REGS_APB_DP_AUX_RX_PRE_MAX_p reset 0x20
  [5:0] AUX_HOST_PRE_MAX rw — Valid maximum length of preamble during receive. The standard defines pre_max = 32
0x2840 V2A__CORE_VP__REGS_APB_DP_AUX_TIMER_PRESET_p reset 0x1D4C
  [15:0] AUX_HOST_TIMER_PRESET rw — The preset value of the timer in DP_IN mode. With sys_clk= 25MHz the Timer can measure up to ~2500 micro seconds. The defaults value is 300us [0x1D4c]
0x2844 V2A__CORE_VP__REGS_APB_DP_AUX_NACK_FORMAT_p reset 0x20
  [7:0] AUX_HOST_NACK_FORMAT rw — Nack or defer pattern for transmit [ 00100000 for defer, 00010000 for nack]
0x2848 V2A__CORE_VP__REGS_APB_DP_AUX_TX_DATA_p
  [9:0] MAILBOX_TX_DATA rw — TX data byte written to the mailbox. It is written 20 times and directly transferred into TX mailbox. First 8 bits are regular data. When the first data is transferred into mailbox mailbox_tx_data[8] [frame start] is set to 1. When the last data is transferred into mailbox, mailbox_tx_data[9] [frame_end] is set to 1.
0x284C V2A__CORE_VP__REGS_APB_DP_AUX_RX_DATA_p
  [9:0] MAILBOX_RX_DATA ro — Read data from the mailbox. Whenever read to this register occurs, aux_mailbox_read to RX Mailbox shall be asserted for one clock cycle.
0x2850 V2A__CORE_VP__REGS_APB_DP_AUX_TX_STATUS_p reset 0x101
  [9] MAILBOX_TX_FULL ro — AUX Mailbox TX full flag.
  [8] MAILBOX_TX_EMPTY ro — AUX Mailbox TX empty flag.
  [7] AUX_TX_FRAME_ONGOING ro — Frame transmission status.
  [6:0] AUX_TX_STATE ro — Aux_tx state machine register.
0x2854 V2A__CORE_VP__REGS_APB_DP_AUX_RX_STATUS_p reset 0x1010141
  [31:24] AUX_RX_DATA_STATE ro — AUX_RX SM state.
  [23] AUX_MAIN_RX_STATUS_LAST_EQUAL ro — The receive transaction is equal to the previous transaction.
  [19:16] AUX_RX_HHLL_STATE ro — AUX_RX hhll state machine register.
  [13:8] AUX_RX_PREAMBLE_STATE ro — AUX_RX preamble state machine register. Used only for debug.
  [7] MAILBOX_RX_FULL ro — AUX Mailbox RX full flag.
  [6] MAILBOX_RX_EMPTY ro — AUX Mailbox RX empty flag.
  [5] AUX_RX_FRAME_ONGOING ro — Frame reception status.
  [4:0] AUX_RX_MAIN_STATE ro — AUX_RX main state machine register. Used only for debug purpose.
0x2858 V2A__CORE_VP__REGS_APB_DP_AUX_RX_CYCLE_COUNTER_p
  [10:0] AUX_RX_CYCLE_COUNTER ro — Count system clocks from last change in the auxiliary line input.
0x285C V2A__CORE_VP__REGS_APB_DP_AUX_MAIN_STATES_p
  [13:10] AUX_MAIN_EXTERNAL_STATE ro — AUX_MAIN external state machine register.
  [9:8] AUX_MAIN_TIMER_STATE ro — AUX_MAIN timer state machine.
  [6:5] AUX_MAIN_DP_STATE ro — AUX_MAIN dp state machine.
  [4:2] AUX_MAIN_RX_STATE ro — AUX_MAIN rx state machine.
  [1:0] AUX_MAIN_TX_STATE ro — AUX_MAIN tx state machine.
0x2860 V2A__CORE_VP__REGS_APB_DP_AUX_MAIN_TIMER_p
  [15:0] AUX_MAIN_TIMER ro — DP_AUX MAIN timer status.
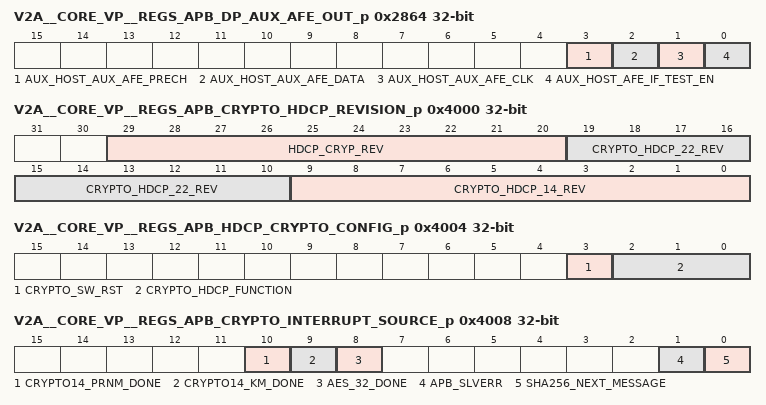
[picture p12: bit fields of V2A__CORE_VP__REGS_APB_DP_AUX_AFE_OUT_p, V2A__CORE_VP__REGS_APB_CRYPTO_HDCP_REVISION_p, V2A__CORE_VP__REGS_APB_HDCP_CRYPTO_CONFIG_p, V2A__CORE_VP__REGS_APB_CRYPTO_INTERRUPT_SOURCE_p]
0x2864 V2A__CORE_VP__REGS_APB_DP_AUX_AFE_OUT_p
  [3] AUX_HOST_AUX_AFE_PRECH rw — Drive the aux_data_prech output to the AFE when aux_host_afe_if_test_en [bit 0 ] is set.
  [2] AUX_HOST_AUX_AFE_DATA rw — Drive the aux_data_out output to the AFE when aux_host_afe_if_test_en [bit 0 ] is set.
  [1] AUX_HOST_AUX_AFE_CLK rw — Drive the aux_clk_out output to the AFE when aux_host_afe_if_test_en [bit 0 ] is set.
  [0] AUX_HOST_AFE_IF_TEST_EN rw — TESTER mode enable. Give the TESTER direct interface to the AFE_AUX.
0x4000 V2A__CORE_VP__REGS_APB_CRYPTO_HDCP_REVISION_p
  [29:20] HDCP_CRYP_REV ro — Revision of the HDCP Crypto block.
  [19:10] CRYPTO_HDCP_22_REV ro — Revision of the HDCP Crypto 2.2 block.
  [9:0] CRYPTO_HDCP_14_REV ro — Revision of the HDCP Crypto 1.4 block.
0x4004 V2A__CORE_VP__REGS_APB_HDCP_CRYPTO_CONFIG_p
  [3] CRYPTO_SW_RST rw — Software reset for the Crypto module.
  [2:0] CRYPTO_HDCP_FUNCTION rw — Enables a version of the Crypto function: 0x0 - HDCP 1.4 0x1 - HDCP 2.2 Other - Reserved
0x4008 V2A__CORE_VP__REGS_APB_CRYPTO_INTERRUPT_SOURCE_p
  [10] CRYPTO14_PRNM_DONE ro — LFSR and block output finished calculation. Active HIGH. Clear on read.
  [9] CRYPTO14_KM_DONE ro — Done reading/calculating Km. Active HIGH. Clear on read.
  [8] AES_32_DONE ro — Asserted when the rising edge of the AES-32 done output is detected. Active HIGH. Clear on read.
  [1] APB_SLVERR ro — APB slave error. Asserted when APB address is out of address range. Active HIGH. Clear on read.
  [0] SHA256_NEXT_MESSAGE ro — Asserted when the rising edge of the SHA256 done output is detected. Active HIGH. Clear on read.
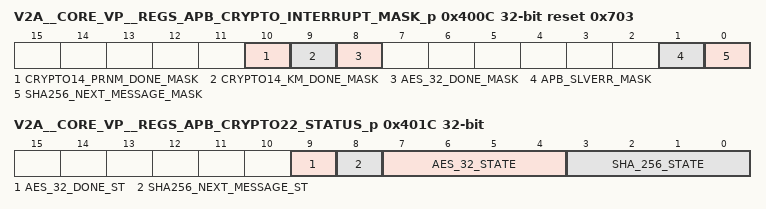
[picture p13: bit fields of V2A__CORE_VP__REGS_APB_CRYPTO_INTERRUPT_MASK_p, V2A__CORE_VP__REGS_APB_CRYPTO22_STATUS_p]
0x400C V2A__CORE_VP__REGS_APB_CRYPTO_INTERRUPT_MASK_p reset 0x703
  [10] CRYPTO14_PRNM_DONE_MASK rw — Set to 1 to mask the crypto14_prnm_done interrupt. 0x0-interrupt enabled 0x1-interrupt disabled
  [9] CRYPTO14_KM_DONE_MASK rw — Set to 1 to mask the crypto14_km_done interrupt. 0x0-interrupt enabled 0x1-interrupt disabled
  [8] AES_32_DONE_MASK rw — Set to 1 to mask the AES32_done interrupt. 0x0-interrupt enabled 0x1-interrupt disabled
  [1] APB_SLVERR_MASK rw — Set to 1 for the apb_slverr interrupt. 0x0-interrupt enabled 0x1-interrupt disabled
  [0] SHA256_NEXT_MESSAGE_MASK rw — Set to 1 to mask the SHA256_done interrupt. 0x0-interrupt enabled 0x1-interrupt disabled
0x4018 V2A__CORE_VP__REGS_APB_CRYPTO22_CONFIG_p
  [0] SHA_256_START rw — Set to 1 for Sha-256 start.
0x401C V2A__CORE_VP__REGS_APB_CRYPTO22_STATUS_p
  [9] AES_32_DONE_ST ro — Asserted when the rising edge of the AES-32 done output is detected.
  [8] SHA256_NEXT_MESSAGE_ST ro — Asserted when the SHA-256 module is ready to receive the next message.
  [7:4] AES_32_STATE ro — AES-32 current state.
  [3:0] SHA_256_STATE ro — SHA-256 current state.
0x403C V2A__CORE_VP__REGS_APB_SHA_256_DATA_IN_p rw
  [31:0] SHA_256_DATA_IN — Holds the 32-bit input data word of the SHA-256 module.
0x4050 V2A__CORE_VP__REGS_APB_SHA_256_DATA_OUT_0_p ro
  [31:0] SHA_256_DATA_OUT_0 — Holds the least significant 32-bits word of the 256-bits output data word of the SHA-256 module.
0x4054 V2A__CORE_VP__REGS_APB_SHA_256_DATA_OUT_1_p ro
  [31:0] SHA_256_DATA_OUT_1 — Holds the next significant 32-bits word of the 256-bits output data word of the SHA-256 module.
0x4058 V2A__CORE_VP__REGS_APB_SHA_256_DATA_OUT_2_p ro
  [31:0] SHA_256_DATA_OUT_2 — Holds the next significant 32-bits word of the 256-bits output data word of the SHA-256 module
{0x4050+4i} V2A__CORE_VP__REGS_APB_SHA_256_DATA_OUT_{i}_p ro (i=3..6)
  [31:0] SHA_256_DATA_OUT_{i} — Holds the next significant 32-bits word of the 256-bits output data word of the SHA-256 module.
0x406C V2A__CORE_VP__REGS_APB_SHA_256_DATA_OUT_7_p ro
  [31:0] SHA_256_DATA_OUT_7 — Holds the most significant 32-bits word of the 256-bits output data word of the SHA-256 module.
0x4070 V2A__CORE_VP__REGS_APB_AES_32_KEY_0_p rw
  [31:0] AES_32_KEY_0 — Holds the least significant 32-bits word of the 128-bits input key word of the AES-32 module.
0x4074 V2A__CORE_VP__REGS_APB_AES_32_KEY_1_p rw
  [31:0] AES_32_KEY_1 — Holds the next significant 32-bits word of the 128-bits input key word of the AES-32 module.
0x4078 V2A__CORE_VP__REGS_APB_AES_32_KEY_2_p rw
  [31:0] AES_32_KEY_2 — Holds the next significant 32-bits word of the 128-bits input key word of the AES-32 module.
0x407C V2A__CORE_VP__REGS_APB_AES_32_KEY_3_p rw
  [31:0] AES_32_KEY_3 — Holds the most significant 32-bits word of the 128-bits input key word of the AES-32 module.
0x4080 V2A__CORE_VP__REGS_APB_AES_32_DATA_IN_p rw
  [31:0] AES_32_DATA_IN — Holds the input data word to the AES-32 module.
0x4084 V2A__CORE_VP__REGS_APB_AES_32_DATA_OUT_0_p ro
  [31:0] AES_32_DATA_OUT_0 — Holds the least significant 32-bits word of the 128-bits output data word of the AES-32 module.
0x4088 V2A__CORE_VP__REGS_APB_AES_32_DATA_OUT_1_p ro
  [31:0] AES_32_DATA_OUT_1 — Holds the next significant 32-bits word of the 128-bits output data word of the AES-32 module.
0x408C V2A__CORE_VP__REGS_APB_AES_32_DATA_OUT_2_p ro
  [31:0] AES_32_DATA_OUT_2 — Holds the next significant 32-bits word of the 128-bits output data word of the AES-32 module.
0x4090 V2A__CORE_VP__REGS_APB_AES_32_DATA_OUT_3_p ro
  [31:0] AES_32_DATA_OUT_3 — Holds the most significant 32-bits word of the 128-bits output data word of the AES-32 module.
